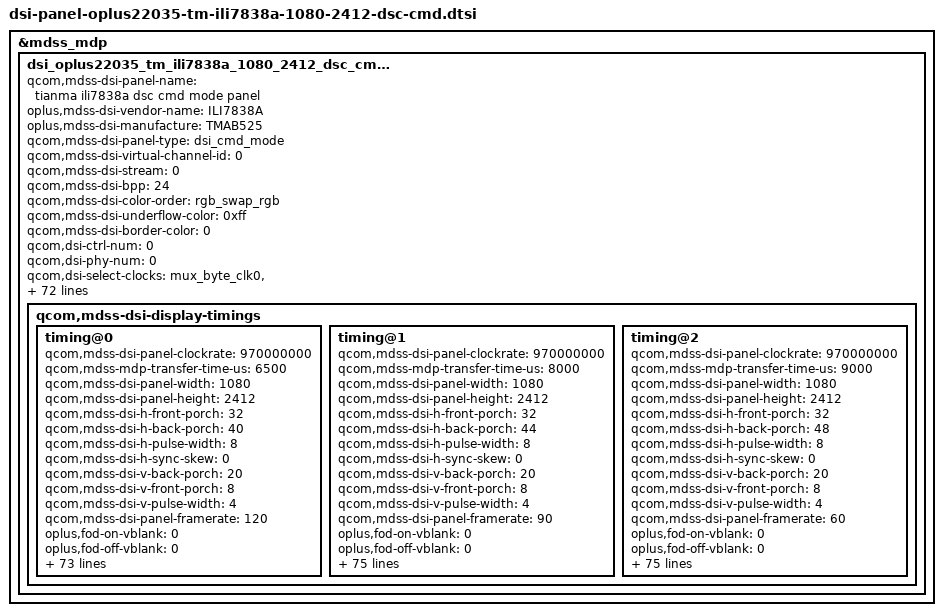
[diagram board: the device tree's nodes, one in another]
&mdss_mdp {
	dsi_oplus22035_tm_ili7838a_1080_2412_dsc_cmd: qcom,mdss_dsi_oplus22035_tm_ili7838a_1080_2412_dsc_cmd {
		qcom,mdss-dsi-panel-name = "tianma ili7838a dsc cmd mode panel";
		oplus,mdss-dsi-vendor-name = "ILI7838A";
		oplus,mdss-dsi-manufacture = "TMAB525";
		qcom,mdss-dsi-panel-type = "dsi_cmd_mode";
		qcom,mdss-dsi-virtual-channel-id = <0>;
		qcom,mdss-dsi-stream = <0>;
		qcom,mdss-dsi-bpp = <24>;
		qcom,mdss-dsi-color-order = "rgb_swap_rgb";
		qcom,mdss-dsi-underflow-color = <0xff>;
		qcom,mdss-dsi-border-color = <0>;
		qcom,dsi-ctrl-num = <0>;
		qcom,dsi-phy-num = <0>;
		qcom,dsi-select-clocks = "src_byte_clk0", "src_pixel_clk0";

		qcom,mdss-dsi-traffic-mode = "non_burst_sync_event";
		qcom,mdss-dsi-lane-map = "lane_map_0123";
		qcom,mdss-dsi-bllp-eof-power-mode;
		qcom,mdss-dsi-bllp-power-mode;
		qcom,mdss-dsi-lane-0-state;
		qcom,mdss-dsi-lane-1-state;
		qcom,mdss-dsi-lane-2-state;
		qcom,mdss-dsi-lane-3-state;
		qcom,mdss-dsi-dma-trigger = "trigger_sw";
		qcom,mdss-dsi-mdp-trigger = "none";
		qcom,mdss-dsi-reset-sequence = <1 10>, <0 10>, <1 10>;
		qcom,mdss-dsi-te-pin-select = <1>;
		qcom,mdss-dsi-te-dcs-command = <1>;
		qcom,mdss-dsi-te-check-enable;
		qcom,mdss-dsi-te-using-te-pin;
		qcom,mdss-dsi-wr-mem-start = <0x2c>;
		qcom,mdss-dsi-wr-mem-continue = <0x3c>;
		qcom,mdss-dsi-panel-hdr-enabled;
		qcom,mdss-dsi-panel-hdr-color-primaries = <15000 15500 34000
			16000 13250 34500 7500 3000>;
		qcom,mdss-dsi-panel-peak-brightness = <4300000>;
		qcom,mdss-dsi-panel-blackness-level = <1023>;
		qcom,mdss-pan-physical-width-dimension = <70>;
		qcom,mdss-pan-physical-height-dimension = <155>;
		qcom,mdss-dsi-lp11-init;
		qcom,esd-check-enabled;
		qcom,mdss-dsi-panel-status-check-mode = "reg_read";
		qcom,mdss-dsi-panel-status-command = [06 01 00 01 05 00 02 0A 00];
		qcom,mdss-dsi-panel-status-command-state = "dsi_lp_mode";
		qcom,mdss-dsi-panel-status-value = <0x9C>;
		qcom,mdss-dsi-panel-status-read-length = <1>;

		qcom,mdss-dsi-display-timings {
		timing@0{
				qcom,mdss-dsi-panel-clockrate = <970000000>;
				qcom,mdss-mdp-transfer-time-us = <6500>;
				qcom,mdss-dsi-panel-width = <1080>;
				qcom,mdss-dsi-panel-height = <2412>;
				qcom,mdss-dsi-h-front-porch = <32>;
				qcom,mdss-dsi-h-back-porch = <40>;
				qcom,mdss-dsi-h-pulse-width = <8>;
				qcom,mdss-dsi-h-sync-skew = <0>;
				qcom,mdss-dsi-v-back-porch = <20>;
				qcom,mdss-dsi-v-front-porch = <8>;
				qcom,mdss-dsi-v-pulse-width = <4>;
				qcom,mdss-dsi-panel-framerate = <120>;
				oplus,fod-on-vblank = <0>;
				oplus,fod-off-vblank = <0>;
				qcom,mdss-dsi-on-command = [
					//APL Peak Luminance ON
					39 01 00 00 00 00 04 FF 78 38 0B
					39 01 00 00 00 00 02 17 F3
					39 01 00 00 00 00 02 18 F3
					39 01 00 00 00 00 02 19 F3
					39 01 00 00 00 00 02 1A F3
					39 01 00 00 00 00 02 1B F3
					39 01 00 00 00 00 02 1C F3
					39 01 00 00 00 00 02 1D F3
					39 01 00 00 00 00 04 FF 78 38 0A
					39 01 00 00 00 00 02 37 4F
					39 01 00 00 00 00 02 38 70
					39 01 00 00 00 00 04 FF 78 38 00
					39 01 00 00 00 00 02 55 03

					//R Corner Control off
					39 01 00 00 00 00 04 FF 78 38 17
					39 01 00 00 00 00 02 20 00
					//osc121.5Mhz
					39 01 00 00 00 00 04 FF 78 38 0F
					39 01 00 00 00 00 02 6E 12
					//NVM Reload
					39 01 00 00 00 00 04 FF 78 38 08
					39 01 00 00 00 00 02 45 4C

					////spr 优化-
					39 01 00 00 00 00 04 FF 78 38 14
					39 01 00 00 00 00 09 12 00 00 40 40 00 00 00 00
					39 01 00 00 00 00 09 16 00 00 80 00 00 00 00 00
					39 01 00 00 00 00 13 20 40 80 00 00 80 40 00 00 00 00 80 40 40 80 00 00 00 00
					39 01 00 00 00 00 09 22 00 00 00 04 04 00 60 80
					39 01 00 00 00 00 04 FF 78 38 15

					39 01 00 00 00 00 43 00 00
					00 02 00 02 10 03 00 04 00
					05 00 05 10 06 00 06 10 07
					02 08 0d 09 1a 0b 0b 0e 19
					12 19 17 09 1c 0c 21 1e 28
					02 2e 17 35 1e 3d 1c 46 09
					4f 06 58 18 6d 16 79 07 85
					0d 9f 01 bb 0e da 0c fb 1d
					00 0a

					39 01 00 00 00 00 43 50 00
					00 04 00 08 00 0c 00 10 00
					14 00 18 00 1c 00 24 00 2c
					00 30 02 31 00 34 03 39 0f
					3f 01 43 0c 48 01 4f 0e 56
					0d 5d 03 68 09 72 0a 7b 0b
					84 01 93 02 a0 08 ac 0a b7
					0e cc 02 de 04 ee 0b fd 0f
					ff 0c

					39 01 00 00 00 00 04 FF 78 38 0E
					39 01 00 00 00 00 13 38 40 80 00 00 80 40 00 00 00 00 80 40 40 80 00 00 00 00
					//backlight time-
					39 01 00 00 00 00 04 FF 78 38 0C
					39 01 00 00 00 00 02 BD C4
					//120HZ
					39 01 00 00 00 00 04 FF 78 38 02
					39 01 00 00 00 00 02 38 11

					//dsc 8bit
					39 01 00 00 00 00 04 FF 78 38 07
					39 01 00 00 00 00 02 29 01

					39 01 00 00 00 00 64 20 00 00 00
						00 00 11 00 00 ab 30 A0 09 6c 04
						38 00 0c 02 1c 02 a3 01 9a 01 d8
						00 19 01 03 00 0a 00 0c 08 bb 0a
						5f 16 00 10 ec 07 10 20 00 06 0f
						0f 33 0e 1c 2a 38 46 54 62 69 70
						77 79 7b 7d 7e 01 c2 22 00 2a 40
						32 be 3a fc 3a fa 3a f8 3b 38 3b
						78 3b 76 4b b6 4b b6 4b f4 5b f4
						7c 34 00 00 00 00 00 00

					//RTN SETTING-
					39 01 00 00 00 00 04 FF 78 38 02
					39 01 00 00 00 00 02 32 79
					39 01 00 00 00 00 02 34 79
					39 01 00 00 00 00 02 36 79

					//demura Reload NG 强制demura on-
					39 01 00 00 00 00 04 FF 78 38 19
					39 01 00 00 00 00 02 E0 88
					39 01 00 00 00 00 04 FF 78 38 08
					39 01 00 00 00 00 02 96 3F
					39 01 00 00 00 00 02 B0 81
					39 01 00 00 00 00 04 FF 78 38 06
					39 01 00 00 00 00 02 C9 A0

					//IR IP ON
					39 01 00 00 00 00 04 FF 78 38 00
					39 01 00 00 00 00 02 95 10

					//TE ON
					39 01 00 00 00 00 04 FF 78 38 00
					39 01 00 00 00 00 02 35 00

					//Dimming Setting
					39 01 00 00 00 00 02 53 20

					//Sleep out
					05 01 00 00 79 00 01 11
					05 01 00 00 14 00 01 29
				];
				qcom,mdss-dsi-post-on-backlight = [
				];
				qcom,mdss-dsi-timing-switch-command = [
					/* 120hz Transition */
					39 01 00 00 00 00 04 FF 78 38 02
					39 01 00 00 00 00 02 38 11
					39 01 00 00 00 00 04 FF 78 38 00
				];
				qcom,mdss-dsi-off-command = [
					05 01 00 00 0A 00 01 28
					05 01 00 00 78 00 01 10
				];
				qcom,mdss-dsi-lp1-command = [
					/* AOD Mode ON */
					39 00 00 00 00 00 04 FF 78 38 00
					05 00 00 00 00 00 01 39
					39 00 00 00 00 00 04 FF 78 38 0C
					15 00 00 00 00 00 02 BE 01
					39 01 00 00 00 00 04 FF 78 38 00
				];
				qcom,mdss-dsi-nolp-command = [
					/* AOD Mode OFF */
					39 00 00 00 00 00 04 FF 78 38 00
					05 01 00 00 00 00 01 38
				];
				qcom,mdss-dsi-aod-high-mode-command = [
					/* AOD High Mode, 50nit */
					39 00 00 00 00 00 04 FF 78 38 0C
					15 00 00 00 00 00 02 BE 01
					39 01 00 00 22 00 04 FF 78 38 00
				];
				qcom,mdss-dsi-aod-low-mode-command = [
					/* AOD Low Mode 10nit */
					39 00 00 00 00 00 04 FF 78 38 0C
					15 00 00 00 00 00 02 BE 00
					39 01 00 00 22 00 04 FF 78 38 00
				];
				qcom,mdss-dsi-aod-hbm-on-command = [
					/* AOD Mode OFF */
					39 00 00 00 00 00 04 FF 78 38 00
					05 01 00 00 09 00 01 38
					/*HBM ON */
					39 01 00 00 00 00 03 51 0F FF
				];
				qcom,mdss-dsi-hbm-on-command = [
					39 01 00 00 00 00 03 51 0F FF
				];
				qcom,mdss-dsi-hbm-off-command = [
				];
				qcom,mdss-dsi-aod-hbm-off-command = [
					/*HBM OFF */
					39 01 00 00 09 00 03 51 00 00
					/* AOD Mode ON */
					39 00 00 00 00 00 04 FF 78 38 00
					05 00 00 00 00 00 01 39
					39 00 00 00 00 00 04 FF 78 38 0C
					15 00 00 00 00 00 02 BE 01
					39 01 00 00 00 00 04 FF 78 38 00
				];
				qcom,mdss-dsi-seed-off-command = [
				];
				qcom,mdss-dsi-seed-0-command = [
				];
				qcom,mdss-dsi-seed-1-command = [
				];
				qcom,mdss-dsi-seed-2-command = [
				];
				qcom,mdss-dsi-osc-clk-mode0-command = [
					/* OSC 121.5MHz */
					39 01 00 00 00 00 04 FF 78 38 0F
					39 01 00 00 00 00 02 6E 12
					39 01 00 00 00 00 04 FF 78 38 00

				];
				qcom,mdss-dsi-osc-clk-mode1-command = [
					/* OSC 128MHz */
					39 01 00 00 00 00 04 FF 78 38 0F
					39 01 00 00 00 00 02 6E 13
					39 01 00 00 00 00 04 FF 78 38 00

				];
				qcom,mdss-dsi-hbm-enter-switch-command = [
				];
				qcom,mdss-dsi-hbm-exit-switch-command = [
				];
				qcom,mdss-dsi-aod-hbm-on-command-state = "dsi_lp_mode";
				qcom,mdss-dsi-aod-hbm-off-command-state = "dsi_lp_mode";
				qcom,mdss-dsi-hbm-on-command-state = "dsi_lp_mode";
				qcom,mdss-dsi-seed-off-command-state = "dsi_lp_mode";
				qcom,mdss-dsi-seed-0-command-state = "dsi_lp_mode";
				qcom,mdss-dsi-seed-1-command-state = "dsi_lp_mode";
				qcom,mdss-dsi-seed-2-command-state = "dsi_lp_mode";
				qcom,mdss-dsi-osc-clk-mode0-command-state = "dsi_lp_mode";
				qcom,mdss-dsi-osc-clk-mode1-command-state = "dsi_lp_mode";
				qcom,mdss-dsi-lp1-command-state = "dsi_lp_mode";
				qcom,mdss-dsi-aod-high-mode-command-state = "dsi_lp_mode";
				qcom,mdss-dsi-aod-low-mode-command-state = "dsi_lp_mode";
				qcom,mdss-dsi-nolp-command-state = "dsi_lp_mode";
				qcom,mdss-dsi-post-on-backlight-state = "dsi_lp_mode";
				qcom,mdss-dsi-timing-switch-command-state = "dsi_lp_mode";
				qcom,mdss-dsi-on-command-state = "dsi_lp_mode";
				qcom,mdss-dsi-off-command-state = "dsi_lp_mode";
				qcom,compression-mode = "dsc";
				qcom,mdss-dsc-slice-height = <12>;
				qcom,mdss-dsc-slice-width = <540>;
				qcom,mdss-dsc-slice-per-pkt = <2>;
				qcom,mdss-dsc-bit-per-component = <8>;
				qcom,mdss-dsc-bit-per-pixel = <8>;
				qcom,mdss-dsc-block-prediction-enable;
			};
			timing@1{
				qcom,mdss-dsi-panel-clockrate = <970000000>;
				qcom,mdss-mdp-transfer-time-us = <8000>;
				qcom,mdss-dsi-panel-width = <1080>;
				qcom,mdss-dsi-panel-height = <2412>;
				qcom,mdss-dsi-h-front-porch = <32>;
				qcom,mdss-dsi-h-back-porch = <44>;
				qcom,mdss-dsi-h-pulse-width = <8>;
				qcom,mdss-dsi-h-sync-skew = <0>;
				qcom,mdss-dsi-v-back-porch = <20>;
				qcom,mdss-dsi-v-front-porch = <8>;
				qcom,mdss-dsi-v-pulse-width = <4>;
				qcom,mdss-dsi-panel-framerate = <90>;
				oplus,fod-on-vblank = <0>;
				oplus,fod-off-vblank = <0>;
				/* Apollo vsync config, need to measure TE signal */
				oplus,apollo-panel-vsync-width = <5680>;
				oplus,apollo-panel-vsync-period = <16850>;

				qcom,mdss-dsi-on-command = [
					//APL Peak Luminance ON
					39 01 00 00 00 00 04 FF 78 38 0B
					39 01 00 00 00 00 02 17 F3
					39 01 00 00 00 00 02 18 F3
					39 01 00 00 00 00 02 19 F3
					39 01 00 00 00 00 02 1A F3
					39 01 00 00 00 00 02 1B F3
					39 01 00 00 00 00 02 1C F3
					39 01 00 00 00 00 02 1D F3
					39 01 00 00 00 00 04 FF 78 38 0A
					39 01 00 00 00 00 02 37 4F
					39 01 00 00 00 00 02 38 70
					39 01 00 00 00 00 04 FF 78 38 00
					39 01 00 00 00 00 02 55 03

					//R Corner Control off
					39 01 00 00 00 00 04 FF 78 38 17
					39 01 00 00 00 00 02 20 00

					//NVM Reload
					39 01 00 00 00 00 04 FF 78 38 08
					39 01 00 00 00 00 02 45 4C
					//osc121.5Mhz
					39 01 00 00 00 00 04 FF 78 38 0F
					39 01 00 00 00 00 02 6E 12

					////spr 优化-
					39 01 00 00 00 00 04 FF 78 38 14
					39 01 00 00 00 00 09 12 00 00 40 40 00 00 00 00
					39 01 00 00 00 00 09 16 00 00 80 00 00 00 00 00
					39 01 00 00 00 00 13 20 40 80 00 00 80 40 00 00 00 00 80 40 40 80 00 00 00 00
					39 01 00 00 00 00 09 22 00 00 00 04 04 00 60 80
					39 01 00 00 00 00 04 FF 78 38 15

					39 01 00 00 00 00 43 00 00
					00 02 00 02 10 03 00 04 00
					05 00 05 10 06 00 06 10 07
					02 08 0d 09 1a 0b 0b 0e 19
					12 19 17 09 1c 0c 21 1e 28
					02 2e 17 35 1e 3d 1c 46 09
					4f 06 58 18 6d 16 79 07 85
					0d 9f 01 bb 0e da 0c fb 1d
					00 0a

					39 01 00 00 00 00 43 50 00
					00 04 00 08 00 0c 00 10 00
					14 00 18 00 1c 00 24 00 2c
					00 30 02 31 00 34 03 39 0f
					3f 01 43 0c 48 01 4f 0e 56
					0d 5d 03 68 09 72 0a 7b 0b
					84 01 93 02 a0 08 ac 0a b7
					0e cc 02 de 04 ee 0b fd 0f
					ff 0c

					39 01 00 00 00 00 04 FF 78 38 0E
					39 01 00 00 00 00 13 38 40 80 00 00 80 40 00 00 00 00 80 40 40 80 00 00 00 00
					//backlight time-
					39 01 00 00 00 00 04 FF 78 38 0C
					39 01 00 00 00 00 02 BD C4
					//90HZ
					39 01 00 00 00 00 04 FF 78 38 02
					39 01 00 00 00 00 02 38 12

					//dsc 8bit
					39 01 00 00 00 00 04 FF 78 38 07
					39 01 00 00 00 00 02 29 01

					39 01 00 00 00 00 64 20 00 00 00
						00 00 11 00 00 ab 30 A0 09 6c 04
						38 00 0c 02 1c 02 a3 01 9a 01 d8
						00 19 01 03 00 0a 00 0c 08 bb 0a
						5f 16 00 10 ec 07 10 20 00 06 0f
						0f 33 0e 1c 2a 38 46 54 62 69 70
						77 79 7b 7d 7e 01 c2 22 00 2a 40
						32 be 3a fc 3a fa 3a f8 3b 38 3b
						78 3b 76 4b b6 4b b6 4b f4 5b f4
						7c 34 00 00 00 00 00 00

					//RTN SETTING-
					39 01 00 00 00 00 04 FF 78 38 02
					39 01 00 00 00 00 02 32 79
					39 01 00 00 00 00 02 34 79
					39 01 00 00 00 00 02 36 79

					//demura Reload NG 强制demura on-
					39 01 00 00 00 00 04 FF 78 38 19
					39 01 00 00 00 00 02 E0 88
					39 01 00 00 00 00 04 FF 78 38 08
					39 01 00 00 00 00 02 96 3F
					39 01 00 00 00 00 02 B0 81
					39 01 00 00 00 00 04 FF 78 38 06
					39 01 00 00 00 00 02 C9 A0

					//IR IP ON
					39 01 00 00 00 00 04 FF 78 38 00
					39 01 00 00 00 00 02 95 10

					//TE ON
					39 01 00 00 00 00 04 FF 78 38 00
					39 01 00 00 00 00 02 35 00

					//Dimming Setting
					39 01 00 00 00 00 02 53 20
					//Sleep out
					05 01 00 00 79 00 01 11
					05 01 00 00 14 00 01 29
				];
				qcom,mdss-dsi-post-on-backlight = [
				];
				qcom,mdss-dsi-timing-switch-command = [
					/* 90hz Transition */
					39 01 00 00 00 00 04 FF 78 38 02
					39 01 00 00 00 00 02 38 12
					39 01 00 00 00 00 04 FF 78 38 00
				];
				qcom,mdss-dsi-off-command = [
					05 01 00 00 0A 00 01 28
					05 01 00 00 78 00 01 10
				];
				qcom,mdss-dsi-lp1-command = [
					/* AOD Mode ON */
					39 00 00 00 00 00 04 FF 78 38 00
					05 00 00 00 00 00 01 39
					39 00 00 00 00 00 04 FF 78 38 0C
					15 00 00 00 00 00 02 BE 01
					39 01 00 00 00 00 04 FF 78 38 00
				];
				qcom,mdss-dsi-nolp-command = [
					/* AOD Mode OFF */
					39 00 00 00 00 00 04 FF 78 38 00
					05 01 00 00 00 00 01 38
				];
				qcom,mdss-dsi-aod-high-mode-command = [
					/* AOD High Mode, 50nit */
					39 00 00 00 00 00 04 FF 78 38 0C
					15 00 00 00 00 00 02 BE 01
					39 01 00 00 22 00 04 FF 78 38 00
				];
				qcom,mdss-dsi-aod-low-mode-command = [
					/* AOD Low Mode 10nit */
					39 00 00 00 00 00 04 FF 78 38 0C
					15 00 00 00 00 00 02 BE 00
					39 01 00 00 22 00 04 FF 78 38 00
				];
				qcom,mdss-dsi-aod-hbm-on-command = [
					/* AOD Mode OFF */
					39 00 00 00 00 00 04 FF 78 38 00
					05 01 00 00 0C 00 01 38
					/*HBM ON */
					39 01 00 00 00 00 03 51 0F FF
				];
				qcom,mdss-dsi-hbm-on-command = [
					39 01 00 00 00 00 03 51 0F FF
				];
				qcom,mdss-dsi-hbm-off-command = [
				];
				qcom,mdss-dsi-aod-hbm-off-command = [
					/*HBM OFF */
					39 01 00 00 0C 00 03 51 00 00
					/* AOD Mode ON */
					39 00 00 00 00 00 04 FF 78 38 00
					05 00 00 00 00 00 01 39
					39 00 00 00 00 00 04 FF 78 38 0C
					15 00 00 00 00 00 02 BE 01
					39 01 00 00 00 00 04 FF 78 38 00
				];
				qcom,mdss-dsi-seed-off-command = [
				];
				qcom,mdss-dsi-seed-0-command = [
				];
				qcom,mdss-dsi-seed-1-command = [
				];
				qcom,mdss-dsi-seed-2-command = [
				];
				qcom,mdss-dsi-osc-clk-mode0-command = [
					/* OSC 121.5MHz */
					39 01 00 00 00 00 04 FF 78 38 0F
					39 01 00 00 00 00 02 6E 12
					39 01 00 00 00 00 04 FF 78 38 00

				];
				qcom,mdss-dsi-osc-clk-mode1-command = [
					/* OSC 128MHz */
					39 01 00 00 00 00 04 FF 78 38 0F
					39 01 00 00 00 00 02 6E 13
					39 01 00 00 00 00 04 FF 78 38 00

				];

				qcom,mdss-dsi-hbm-enter-switch-command = [
				];
				qcom,mdss-dsi-hbm-exit-switch-command = [
				];
				qcom,mdss-dsi-aod-hbm-on-command-state = "dsi_lp_mode";
				qcom,mdss-dsi-aod-hbm-off-command-state = "dsi_lp_mode";
				qcom,mdss-dsi-hbm-on-command-state = "dsi_lp_mode";
				qcom,mdss-dsi-seed-off-command-state = "dsi_lp_mode";
				qcom,mdss-dsi-seed-0-command-state = "dsi_lp_mode";
				qcom,mdss-dsi-seed-1-command-state = "dsi_lp_mode";
				qcom,mdss-dsi-seed-2-command-state = "dsi_lp_mode";
				qcom,mdss-dsi-lp1-command-state = "dsi_lp_mode";
				qcom,mdss-dsi-aod-high-mode-command-state = "dsi_lp_mode";
				qcom,mdss-dsi-aod-low-mode-command-state = "dsi_lp_mode";
				qcom,mdss-dsi-nolp-command-state = "dsi_lp_mode";
				qcom,mdss-dsi-osc-clk-mode0-command-state = "dsi_lp_mode";
				qcom,mdss-dsi-osc-clk-mode1-command-state = "dsi_lp_mode";
				qcom,mdss-dsi-post-on-backlight-state = "dsi_lp_mode";
				qcom,mdss-dsi-timing-switch-command-state = "dsi_lp_mode";
				qcom,mdss-dsi-on-command-state = "dsi_lp_mode";
				qcom,mdss-dsi-off-command-state = "dsi_lp_mode";
				qcom,compression-mode = "dsc";
				qcom,mdss-dsc-slice-height = <12>;
				qcom,mdss-dsc-slice-width = <540>;
				qcom,mdss-dsc-slice-per-pkt = <2>;
				qcom,mdss-dsc-bit-per-component = <8>;
				qcom,mdss-dsc-bit-per-pixel = <8>;
				qcom,mdss-dsc-block-prediction-enable;
			};
			timing@2{
				qcom,mdss-dsi-panel-clockrate = <970000000>;
				qcom,mdss-mdp-transfer-time-us = <9000>;
				qcom,mdss-dsi-panel-width = <1080>;
				qcom,mdss-dsi-panel-height = <2412>;
				qcom,mdss-dsi-h-front-porch = <32>;
				qcom,mdss-dsi-h-back-porch = <48>;
				qcom,mdss-dsi-h-pulse-width = <8>;
				qcom,mdss-dsi-h-sync-skew = <0>;
				qcom,mdss-dsi-v-back-porch = <20>;
				qcom,mdss-dsi-v-front-porch = <8>;
				qcom,mdss-dsi-v-pulse-width = <4>;
				qcom,mdss-dsi-panel-framerate = <60>;
				oplus,fod-on-vblank = <0>;
				oplus,fod-off-vblank = <0>;
				/* Apollo vsync config, need to measure TE signal */
				oplus,apollo-panel-vsync-width = <5680>;
				oplus,apollo-panel-vsync-period = <16850>;

				qcom,mdss-dsi-on-command = [
					//APL Peak Luminance ON
					39 01 00 00 00 00 04 FF 78 38 0B
					39 01 00 00 00 00 02 17 F3
					39 01 00 00 00 00 02 18 F3
					39 01 00 00 00 00 02 19 F3
					39 01 00 00 00 00 02 1A F3
					39 01 00 00 00 00 02 1B F3
					39 01 00 00 00 00 02 1C F3
					39 01 00 00 00 00 02 1D F3
					39 01 00 00 00 00 04 FF 78 38 0A
					39 01 00 00 00 00 02 37 4F
					39 01 00 00 00 00 02 38 70
					39 01 00 00 00 00 04 FF 78 38 00
					39 01 00 00 00 00 02 55 03

					//R Corner Control off
					39 01 00 00 00 00 04 FF 78 38 17
					39 01 00 00 00 00 02 20 00

					//NVM Reload
					39 01 00 00 00 00 04 FF 78 38 08
					39 01 00 00 00 00 02 45 4C
					//osc121.5Mhz
					39 01 00 00 00 00 04 FF 78 38 0F
					39 01 00 00 00 00 02 6E 12

					////spr 优化-
					39 01 00 00 00 00 04 FF 78 38 14
					39 01 00 00 00 00 09 12 00 00 40 40 00 00 00 00
					39 01 00 00 00 00 09 16 00 00 80 00 00 00 00 00
					39 01 00 00 00 00 13 20 40 80 00 00 80 40 00 00 00 00 80 40 40 80 00 00 00 00
					39 01 00 00 00 00 09 22 00 00 00 04 04 00 60 80
					39 01 00 00 00 00 04 FF 78 38 15

					39 01 00 00 00 00 43 00 00
					00 02 00 02 10 03 00 04 00
					05 00 05 10 06 00 06 10 07
					02 08 0d 09 1a 0b 0b 0e 19
					12 19 17 09 1c 0c 21 1e 28
					02 2e 17 35 1e 3d 1c 46 09
					4f 06 58 18 6d 16 79 07 85
					0d 9f 01 bb 0e da 0c fb 1d
					00 0a

					39 01 00 00 00 00 43 50 00
					00 04 00 08 00 0c 00 10 00
					14 00 18 00 1c 00 24 00 2c
					00 30 02 31 00 34 03 39 0f
					3f 01 43 0c 48 01 4f 0e 56
					0d 5d 03 68 09 72 0a 7b 0b
					84 01 93 02 a0 08 ac 0a b7
					0e cc 02 de 04 ee 0b fd 0f
					ff 0c

					39 01 00 00 00 00 04 FF 78 38 0E
					39 01 00 00 00 00 13 38 40 80 00 00 80 40 00 00 00 00 80 40 40 80 00 00 00 00
					//backlight time-
					39 01 00 00 00 00 04 FF 78 38 0C
					39 01 00 00 00 00 02 BD C4
					//60HZ
					39 01 00 00 00 00 04 FF 78 38 02
					39 01 00 00 00 00 02 38 13

					//dsc 8bit
					39 01 00 00 00 00 04 FF 78 38 07
					39 01 00 00 00 00 02 29 01

					39 01 00 00 00 00 64 20 00 00 00
						00 00 11 00 00 ab 30 A0 09 6c 04
						38 00 0c 02 1c 02 a3 01 9a 01 d8
						00 19 01 03 00 0a 00 0c 08 bb 0a
						5f 16 00 10 ec 07 10 20 00 06 0f
						0f 33 0e 1c 2a 38 46 54 62 69 70
						77 79 7b 7d 7e 01 c2 22 00 2a 40
						32 be 3a fc 3a fa 3a f8 3b 38 3b
						78 3b 76 4b b6 4b b6 4b f4 5b f4
						7c 34 00 00 00 00 00 00

					//RTN SETTING-
					39 01 00 00 00 00 04 FF 78 38 02
					39 01 00 00 00 00 02 32 79
					39 01 00 00 00 00 02 34 79
					39 01 00 00 00 00 02 36 79

					//demura Reload NG 强制demura on-
					39 01 00 00 00 00 04 FF 78 38 19
					39 01 00 00 00 00 02 E0 88
					39 01 00 00 00 00 04 FF 78 38 08
					39 01 00 00 00 00 02 96 3F
					39 01 00 00 00 00 02 B0 81
					39 01 00 00 00 00 04 FF 78 38 06
					39 01 00 00 00 00 02 C9 A0

					//IR IP ON
					39 01 00 00 00 00 04 FF 78 38 00
					39 01 00 00 00 00 02 95 10

					//TE ON
					39 01 00 00 00 00 04 FF 78 38 00
					39 01 00 00 00 00 02 35 00

					//Dimming Setting
					39 01 00 00 00 00 02 53 20

					//Sleep out
					05 01 00 00 79 00 01 11
					05 01 00 00 14 00 01 29
				];
				qcom,mdss-dsi-post-on-backlight = [
				];
				qcom,mdss-dsi-timing-switch-command = [
					/* 60hz Transition */
					39 01 00 00 00 00 04 FF 78 38 02
					39 01 00 00 00 00 02 38 13
					39 01 00 00 00 00 04 FF 78 38 00
				];
				qcom,mdss-dsi-off-command = [
					05 01 00 00 0A 00 01 28
					05 01 00 00 78 00 01 10
				];
				qcom,mdss-dsi-lp1-command = [
					/* AOD Mode ON */
					39 00 00 00 00 00 04 FF 78 38 00
					05 00 00 00 00 00 01 39
					39 00 00 00 00 00 04 FF 78 38 0C
					15 00 00 00 00 00 02 BE 01
					39 01 00 00 00 00 04 FF 78 38 00
				];
				qcom,mdss-dsi-nolp-command = [
					/* AOD Mode OFF */
					39 00 00 00 00 00 04 FF 78 38 00
					05 01 00 00 00 00 01 38
				];
				qcom,mdss-dsi-aod-high-mode-command = [
					/* AOD High Mode, 50nit */
					39 00 00 00 00 00 04 FF 78 38 0C
					15 00 00 00 00 00 02 BE 01
					39 01 00 00 22 00 04 FF 78 38 00
				];
				qcom,mdss-dsi-aod-low-mode-command = [
					/* AOD Low Mode 10nit */
					39 00 00 00 00 00 04 FF 78 38 0C
					15 00 00 00 00 00 02 BE 00
					39 01 00 00 22 00 04 FF 78 38 00
				];
				qcom,mdss-dsi-aod-hbm-on-command = [
					/* AOD Mode OFF */
					39 00 00 00 00 00 04 FF 78 38 00
					05 01 00 00 11 00 01 38
					/*HBM ON */
					39 01 00 00 00 00 03 51 0F FF
				];
				qcom,mdss-dsi-hbm-on-command = [
					39 01 00 00 00 00 03 51 0F FF
				];
				qcom,mdss-dsi-hbm-off-command = [
				];
				qcom,mdss-dsi-aod-hbm-off-command = [
					/*HBM OFF */
					39 01 00 00 11 00 03 51 00 00
					/* AOD Mode ON */
					39 00 00 00 00 00 04 FF 78 38 00
					05 00 00 00 00 00 01 39
					39 00 00 00 00 00 04 FF 78 38 0C
					15 00 00 00 00 00 02 BE 01
					39 01 00 00 00 00 04 FF 78 38 00
				];
				qcom,mdss-dsi-seed-off-command = [
				];
				qcom,mdss-dsi-seed-0-command = [
				];
				qcom,mdss-dsi-seed-1-command = [
				];
				qcom,mdss-dsi-seed-2-command = [
				];
				qcom,mdss-dsi-osc-clk-mode0-command = [
					/* OSC 121.5MHz */
					39 01 00 00 00 00 04 FF 78 38 0F
					39 01 00 00 00 00 02 6E 12
					39 01 00 00 00 00 04 FF 78 38 00

				];
				qcom,mdss-dsi-osc-clk-mode1-command = [
					/* OSC 128MHz */
					39 01 00 00 00 00 04 FF 78 38 0F
					39 01 00 00 00 00 02 6E 13
					39 01 00 00 00 00 04 FF 78 38 00

				];
				qcom,mdss-dsi-hbm-enter-switch-command = [
				];
				qcom,mdss-dsi-hbm-exit-switch-command = [
				];
				qcom,mdss-dsi-aod-hbm-on-command-state = "dsi_lp_mode";
				qcom,mdss-dsi-aod-hbm-off-command-state = "dsi_lp_mode";
				qcom,mdss-dsi-hbm-on-command-state = "dsi_lp_mode";
				qcom,mdss-dsi-seed-off-command-state = "dsi_lp_mode";
				qcom,mdss-dsi-seed-0-command-state = "dsi_lp_mode";
				qcom,mdss-dsi-seed-1-command-state = "dsi_lp_mode";
				qcom,mdss-dsi-seed-2-command-state = "dsi_lp_mode";
				qcom,mdss-dsi-lp1-command-state = "dsi_lp_mode";
				qcom,mdss-dsi-aod-high-mode-command-state = "dsi_lp_mode";
				qcom,mdss-dsi-aod-low-mode-command-state = "dsi_lp_mode";
				qcom,mdss-dsi-nolp-command-state = "dsi_lp_mode";
				qcom,mdss-dsi-osc-clk-mode0-command-state = "dsi_lp_mode";
				qcom,mdss-dsi-osc-clk-mode1-command-state = "dsi_lp_mode";
				qcom,mdss-dsi-post-on-backlight-state = "dsi_lp_mode";
				qcom,mdss-dsi-timing-switch-command-state = "dsi_lp_mode";
				qcom,mdss-dsi-on-command-state = "dsi_lp_mode";
				qcom,mdss-dsi-off-command-state = "dsi_lp_mode";
				qcom,compression-mode = "dsc";
				qcom,mdss-dsc-slice-height = <12>;
				qcom,mdss-dsc-slice-width = <540>;
				qcom,mdss-dsc-slice-per-pkt = <2>;
				qcom,mdss-dsc-bit-per-component = <8>;
				qcom,mdss-dsc-bit-per-pixel = <8>;
				qcom,mdss-dsc-block-prediction-enable;
			};
		};
	};
};

&dsi_oplus22035_tm_ili7838a_1080_2412_dsc_cmd {
	qcom,panel-supply-entries = <&dsi_panel_pwr_supply_avdd>;
	qcom,mdss-dsi-bl-pmic-control-type = "bl_ctrl_dcs";
	qcom,mdss-dsi-bl-min-level = <1>;
	qcom,mdss-dsi-bl-max-level = <4095>;
	qcom,mdss-brightness-max-level = <4095>;
	qcom,mdss-dsi-bl-normal-max-level = <3515>;
	qcom,mdss-brightness-normal-max-level = <3515>;
	qcom,mdss-brightness-default-level = <1023>;
	qcom,mdss-dsi-bl-hbm-min-level = <3327>;
	qcom,platform-te-gpio = <&tlmm 23 0>;
	qcom,platform-reset-gpio = <&tlmm 47 0>;
	qcom,bl-update-flag = "delay_until_first_frame";
	oplus,osc-support;
	oplus,disable-53h-control;
	oplus,mdss-dsi-osc-clk-mode0-rate = <167000>;
	oplus,mdss-dsi-osc-clk-mode1-rate = <169000>;
	oplus,dsi-fod-brightness = <0 0xff>,
			<2 0xf3>,
			<4 0xf2>,
			<6 0xef>,
			<8 0xee>,
			<10 0xee>,
			<20 0xee>,
			<36 0xee>,
			<60 0xed>,
			<90 0xed>,
			<140 0xec>,
			<200 0xea>,
			<300 0xe7>,
			<458 0xe2>,
			<605 0xda>,
			<743 0xd2>,
			<912 0xca>,
			<1062 0xc0>,
			<1187 0xb9>,
			<1393 0xae>,
			<1611 0xa1>,
			<1787 0x97>,
			<2000 0x8b>,
			<2200 0x80>,
			<2400 0x75>,
			<2600 0x6a>,
			<2800 0x5e>,
			<3000 0x53>,
			<3200 0x49>,
			<3400 0x3e>,
			<3515 0x37>;
	//oplus,esd-check-flag-enabled;
	qcom,ulps-enabled;
	qcom,suspend-ulps-enabled;
	qcom,dsi-select-clocks = "mux_byte_clk0", "mux_pixel_clk0",
				"src_byte_clk0", "src_pixel_clk0",
				"shadow_byte_clk0", "shadow_pixel_clk0";

	qcom,mdss-dsi-display-timings {
		timing@0{
			qcom,mdss-dsi-panel-phy-timings = [00 21 08 08 19 22 09 08 09 02 04 00 1C 0D];
			qcom,display-topology = <1 1 1>;
			qcom,default-topology-index = <0>;
		};
		timing@1{
			qcom,mdss-dsi-panel-phy-timings = [00 21 08 08 19 22 09 08 09 02 04 00 1C 0D];
			qcom,display-topology = <1 1 1>;
			qcom,default-topology-index = <0>;
		};
		timing@2{
			qcom,mdss-dsi-panel-phy-timings = [00 21 08 08 19 22 09 08 09 02 04 00 1C 0D];
			qcom,display-topology = <1 1 1>;
			qcom,default-topology-index = <0>;
		};
	};
};
&dsi_oplus22035_tm_ili7838a_1080_2412_dsc_cmd {
	qcom,panel_voltage_vddi_name = "vddi";
	qcom,panel_voltage_vddi = <0 1650000 1800000 1950000>;
	qcom,panel_voltage_vddr_name = "vddr";
	qcom,panel_voltage_vddr = <1 1450000 1500000 1600000>;
};
